# MCXN947_cm33_core0 register map
Vendor: nxp.com; File version: 1.0
CPU: CM33 r2p0, little endian, MPU, FPU, VTOR, 3 interrupt priority bits
Registers are 32-bit, read-write, reset 0x0 unless marked. A register's access mark holds for its fields unless they carry their own. Offsets are from the block's base; [hi:lo] are bit positions; {n}, {i} and the like mark numbered series; 'fields as' and 'values as' point back to an identical list.

## ENET0 (part 1 of 2) — ENET
Base 0x40100000
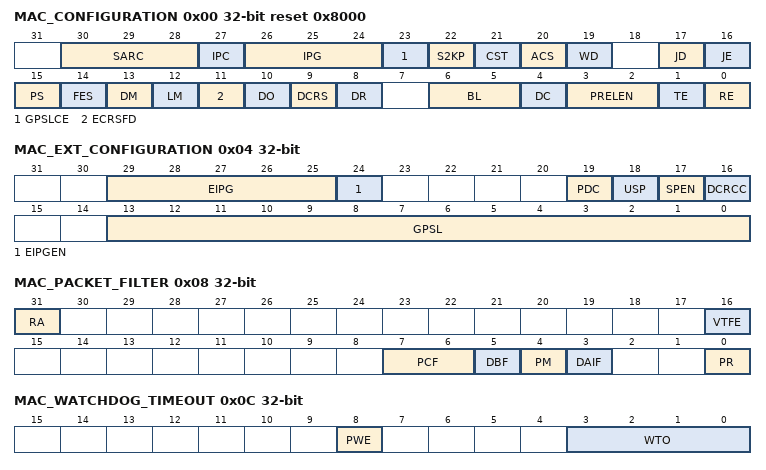
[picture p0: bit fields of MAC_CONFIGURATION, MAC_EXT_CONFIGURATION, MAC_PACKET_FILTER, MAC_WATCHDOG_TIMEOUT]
0x00 MAC_CONFIGURATION reset 0x8000
  [30:28] SARC — Source Address Insertion or Replacement Control
    0=SA_CTRL_IN (mti_sa_ctrl_i and ati_sa_ctrl_i input signals control the SA field generation); 2=MAC0_INS_SA (Contents of MAC Addr-0 inserted in SA field); 3=MAC0_REP_SA (Contents of MAC Addr-0 replaces SA field); 6=MAC1_INS_SA (Contents of MAC Addr-1 inserted in SA field); 7=MAC1_REP_SA (Contents of MAC Addr-1 replaces SA field)
  [27] IPC — Checksum Offload
    0=DISABLE (IP header/payload checksum checking is disabled); 1=ENABLE (IP header/payload checksum checking is enabled)
  [26:24] IPG — Inter-Packet Gap
    0=96 bit times IPG; 1=88 bit times IPG; 2=80 bit times IPG; 3=72 bit times IPG; 4=64 bit times IPG; 5=56 bit times IPG; 6=48 bit times IPG; 7=40 bit times IPG
  [23] GPSLCE — Giant Packet Size Limit Control Enable
    0=DISABLE (Giant Packet Size Limit Control is disabled); 1=ENABLE (Giant Packet Size Limit Control is enabled)
  [22] S2KP — IEEE 802.3as Support for 2K Packets
    0=DISABLE (Support upto 2K packet is disabled); 1=ENABLE (Support upto 2K packet is Enabled)
  [21] CST — CRC stripping for Type packets
    0=DISABLE (CRC stripping for Type packets is disabled); 1=ENABLE (CRC stripping for Type packets is enabled)
  [20] ACS — Automatic Pad or CRC Stripping
    0=DISABLE (Automatic Pad or CRC Stripping is disabled); 1=ENABLE (Automatic Pad or CRC Stripping is enabled)
  [19] WD — Watchdog Disable
    0=ENABLE (Watchdog is enabled); 1=DISABLE (Watchdog is disabled)
  [17] JD — Jabber Disable
    0=ENABLE (Jabber is enabled); 1=DISABLE (Jabber is disabled)
  [16] JE — Jumbo Packet Enable
    0=DISABLE (Jumbo packet is disabled); 1=ENABLE (Jumbo packet is enabled)
  [15] PS ro — Port Select
    0=M_1000_2500M (For 1000 or 2500 Mbps operations); 1=M_10_100M (For 10 or 100 Mbps operations)
  [14] FES — Speed
    0=M_10_1000M (10 Mbps when PS bit is 1 and 1 Gbps when PS bit is 0); 1=M_100_2500M (100 Mbps when PS bit is 1 and 2.5 Gbps when PS bit is 0)
  [13] DM — Duplex Mode
    0=HDUPLX (Half-duplex mode); 1=FDUPLX (Full-duplex mode)
  [12] LM — Loopback Mode
    0=DISABLE (Loopback is disabled); 1=ENABLE (Loopback is enabled)
  [11] ECRSFD — Enable Carrier Sense Before Transmission in Full-Duplex Mode
    0=DISABLE (ECRSFD is disabled); 1=ENABLE (ECRSFD is enabled)
  [10] DO — Disable Receive Own
    0=ENABLE (Enable Receive Own); 1=DISABLE (Disable Receive Own)
  [9] DCRS — Disable Carrier Sense During Transmission
    0=ENABLE (Enable Carrier Sense During Transmission); 1=DISABLE (Disable Carrier Sense During Transmission)
  [8] DR — Disable Retry
    0=ENABLE (Enable Retry); 1=DISABLE (Disable Retry)
  [6:5] BL — Back-Off Limit
    0=MIN_N_10 (k = min(n,10)); 1=MIN_N_8 (k = min(n,8)); 2=MIN_N_4 (k = min(n,4)); 3=MIN_N_1 (k = min(n,1))
  [4] DC — Deferral Check
    0=DISABLE (Deferral check function is disabled); 1=ENABLE (Deferral check function is enabled)
  [3:2] PRELEN — Preamble Length for Transmit packets
    0=M_7BYTES (7 bytes of preamble); 1=M_5BYTES (5 bytes of preamble); 2=M_3BYTES (3 bytes of preamble)
  [1] TE — Transmitter Enable
    0=DISABLE (Transmitter is disabled); 1=ENABLE (Transmitter is enabled)
  [0] RE — Receiver Enable
    0=DISABLE (Receiver is disabled); 1=ENABLE (Receiver is enabled)
0x04 MAC_EXT_CONFIGURATION — MAC Extended Configuration Register
  [29:25] EIPG — Extended Inter-Packet Gap
  [24] EIPGEN — Extended Inter-Packet Gap Enable
    0=DISABLE (Extended Inter-Packet Gap is disabled); 1=ENABLE (Extended Inter-Packet Gap is enabled)
  [19] PDC — Packet Duplication Control
    0=DISABLE (Packet Duplication Control is disabled); 1=ENABLE (Packet Duplication Control is enabled)
  [18] USP — Unicast Slow Protocol Packet Detect
    0=DISABLE (Unicast Slow Protocol Packet Detection is disabled); 1=ENABLE (Unicast Slow Protocol Packet Detection is enabled)
  [17] SPEN — Slow Protocol Detection Enable
    0=DISABLE (Slow Protocol Detection is disabled); 1=ENABLE (Slow Protocol Detection is enabled)
  [16] DCRCC — Disable CRC Checking for Received Packets
    0=ENABLE (CRC Checking is enabled); 1=DISABLE (CRC Checking is disabled)
  [13:0] GPSL — Giant Packet Size Limit
0x08 MAC_PACKET_FILTER
  [31] RA — Receive All
    0=DISABLE (Receive All is disabled); 1=ENABLE (Receive All is enabled)
  [16] VTFE — VLAN Tag Filter Enable
    0=DISABLE (VLAN Tag Filter is disabled); 1=ENABLE (VLAN Tag Filter is enabled)
  [7:6] PCF — Pass Control Packets
    0=FLTR_ALL (MAC filters all control packets from reaching the application); 1=FW_XCPT_PAU (MAC forwards all control packets except Pause packets to the application even if they fail the address filter); 2=FW_ALL (MAC forwards all control packets to the application even if they fail the address filter); 3=FW_PASS (MAC forwards the control packets that pass the Address filter)
  [5] DBF — Disable Broadcast Packets
    0=ENABLE (Enable Broadcast Packets); 1=DISABLE (Disable Broadcast Packets)
  [4] PM — Pass All Multicast
    0=DISABLE (Pass All Multicast is disabled); 1=ENABLE (Pass All Multicast is enabled)
  [3] DAIF — DA Inverse Filtering
    0=DISABLE (DA Inverse Filtering is disabled); 1=ENABLE (DA Inverse Filtering is enabled)
  [0] PR — Promiscuous Mode
    0=DISABLE (Promiscuous Mode is disabled); 1=ENABLE (Promiscuous Mode is enabled)
0x0C MAC_WATCHDOG_TIMEOUT — Watchdog Timeout
  [8] PWE — Programmable Watchdog Enable
    0=DISABLE (Programmable Watchdog is disabled); 1=ENABLE (Programmable Watchdog is enabled)
  [3:0] WTO — Watchdog Timeout
    {v}=bf_{v+2}KBYTES ({v+2} KB) (v=0..13); 14=bf_16383BYTES (16383 Bytes)
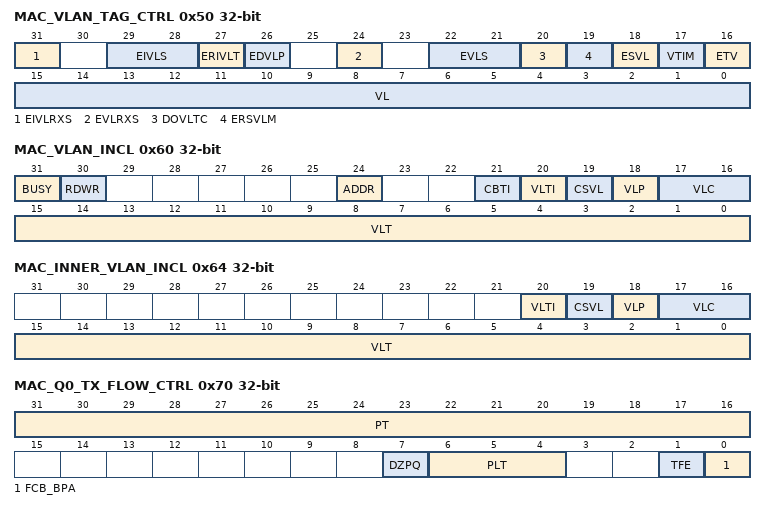
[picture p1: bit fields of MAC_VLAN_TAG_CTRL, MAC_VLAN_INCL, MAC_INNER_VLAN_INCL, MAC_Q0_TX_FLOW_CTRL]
0x50 MAC_VLAN_TAG_CTRL — MAC VLAN Tag Control
  [31] EIVLRXS — Enable Inner VLAN Tag in Rx Status
    0=DISABLE (Inner VLAN Tag in Rx status is disabled); 1=ENABLE (Inner VLAN Tag in Rx status is enabled)
  [29:28] EIVLS — Enable Inner VLAN Tag Stripping on Receive
    0=DONOT (Do not strip); 1=IFPASS (Strip if VLAN filter passes); 2=IFFAIL (Strip if VLAN filter fails); 3=ALWAYS (Always strip)
  [27] ERIVLT — Enable Inner VLAN Tag
    0=DISABLE (Inner VLAN tag is disabled); 1=ENABLE (Inner VLAN tag is enabled)
  [26] EDVLP — Enable Double VLAN Processing
    0=DISABLE (Double VLAN Processing is disabled); 1=ENABLE (Double VLAN Processing is enabled)
  [24] EVLRXS — Enable VLAN Tag in Rx status
    0=DISABLE (VLAN Tag in Rx status is disabled); 1=ENABLE (VLAN Tag in Rx status is enabled)
  [22:21] EVLS — Enable VLAN Tag Stripping on Receive
    values as EIVLS
  [20] DOVLTC — Disable VLAN Type Check
    0=ENABLE (VLAN Type Check is enabled); 1=DISABLE (VLAN Type Check is disabled)
  [19] ERSVLM — Enable Receive S-VLAN Match
    0=DISABLE (Receive S-VLAN Match is disabled); 1=ENABLE (Receive S-VLAN Match is enabled)
  [18] ESVL — Enable S-VLAN
    0=DISABLE (S-VLAN is disabled); 1=ENABLE (S-VLAN is enabled)
  [17] VTIM — VLAN Tag Inverse Match Enable
    0=DISABLE (VLAN Tag Inverse Match is disabled); 1=ENABLE (VLAN Tag Inverse Match is enabled)
  [16] ETV — Enable 12-Bit VLAN Tag Comparison
    0=DISABLE (12-bit VLAN Tag Comparison is disabled); 1=ENABLE (12-bit VLAN Tag Comparison is enabled)
  [15:0] VL — VLAN Tag Identifier for Receive Packets
0x60 MAC_VLAN_INCL — VLAN Tag Inclusion or Replacement
  [31] BUSY ro
    0=INACTIVE (Busy status not detected); 1=ACTIVE (Busy status detected)
  [30] RDWR — Read write control
    0=READ (Read operation of indirect access); 1=WRITE (Write operation of indirect access)
  [24] ADDR — Address
  [21] CBTI — Channel based tag insertion
    0=DISABLE (Channel based tag insertion is disabled); 1=ENABLE (Channel based tag insertion is enabled)
  [20] VLTI — VLAN Tag Input
    0=DISABLE (VLAN Tag Input is disabled); 1=ENABLE (VLAN Tag Input is enabled)
  [19] CSVL — C-VLAN or S-VLAN
    0=C_VLAN (C-VLAN type (0x8100) is inserted or replaced); 1=S_VLAN (S-VLAN type (0x88A8) is inserted or replaced)
  [18] VLP — VLAN Priority Control
    0=DISABLE (VLAN Priority Control is disabled); 1=ENABLE (VLAN Priority Control is enabled)
  [17:16] VLC — VLAN Tag Control in Transmit Packets
    0=NONE (No VLAN tag deletion, insertion, or replacement); 1=DELETE (VLAN tag deletion); 2=INSERT (VLAN tag insertion); 3=REPLACE (VLAN tag replacement)
  [15:0] VLT — VLAN Tag for Transmit Packets
0x64 MAC_INNER_VLAN_INCL — MAC Inner VLAN Tag Inclusion or Replacement
  [20] VLTI — VLAN Tag Input
    values as MAC_VLAN_INCL.VLTI
  [19] CSVL — C-VLAN or S-VLAN
    0=CVLAN (C-VLAN type (0x8100) is inserted); 1=SVLAN (S-VLAN type (0x88A8) is inserted)
  [18] VLP — VLAN Priority Control
    values as MAC_VLAN_INCL.VLP
  [17:16] VLC — VLAN Tag Control in Transmit Packets
    values as MAC_VLAN_INCL.VLC
  [15:0] VLT — VLAN Tag for Transmit Packets
0x70 MAC_Q0_TX_FLOW_CTRL — MAC Q0 Tx Flow Control
  [31:16] PT — Pause Time
  [7] DZPQ — Disable Zero-Quanta Pause
    0=ENABLE (Zero-Quanta Pause packet generation is enabled); 1=DISABLE (Zero-Quanta Pause packet generation is disabled)
  [6:4] PLT — Pause Low Threshold
    0=PT4 (Pause Time minus 4 Slot Times (PT -4 slot times)); 1=PT28 (Pause Time minus 28 Slot Times (PT -28 slot times)); 2=PT36 (Pause Time minus 36 Slot Times (PT -36 slot times)); 3=PT144 (Pause Time minus 144 Slot Times (PT -144 slot times)); 4=PT256 (Pause Time minus 256 Slot Times (PT -256 slot times)); 5=PT512 (Pause Time minus 512 Slot Times (PT -512 slot times))
  [1] TFE — Transmit Flow Control Enable
    0=DISABLE (Transmit Flow Control is disabled); 1=ENABLE (Transmit Flow Control is enabled)
  [0] FCB_BPA — Flow Control Busy or Backpressure Activate
    0=DISABLE (Flow Control Busy or Backpressure Activate is disabled); 1=ENABLE (Flow Control Busy or Backpressure Activate is enabled)
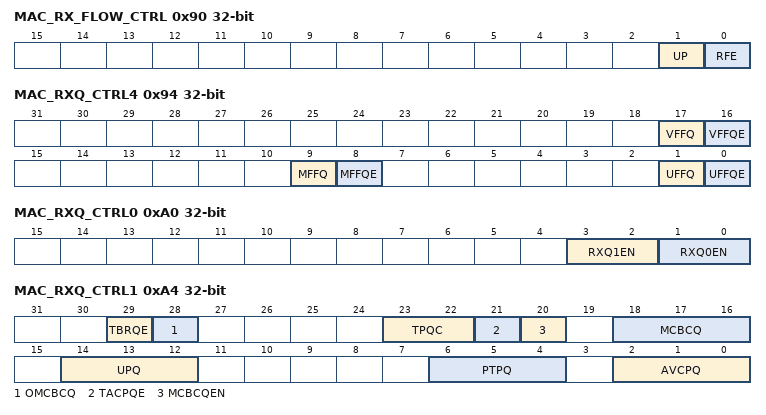
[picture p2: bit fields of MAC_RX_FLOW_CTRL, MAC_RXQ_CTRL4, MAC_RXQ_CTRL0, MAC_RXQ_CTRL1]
0x90 MAC_RX_FLOW_CTRL — MAC Rx Flow Control
  [1] UP — Unicast Pause Packet Detect
    0=DISABLE (Unicast Pause Packet Detect disabled); 1=ENABLE (Unicast Pause Packet Detect enabled)
  [0] RFE — Receive Flow Control Enable
    0=DISABLE (Receive Flow Control is disabled); 1=ENABLE (Receive Flow Control is enabled)
0x94 MAC_RXQ_CTRL4 — Receive Queue Control 4
  [17] VFFQ — VLAN Tag Filter Fail Packets Queue
  [16] VFFQE — VLAN Tag Filter Fail Packets Queuing Enable
    0=DISABLE (VLAN tag Filter Fail Packets Queuing is disabled); 1=ENABLE (VLAN tag Filter Fail Packets Queuing is enabled)
  [9] MFFQ — Multicast Address Filter Fail Packets Queue.
  [8] MFFQE — Multicast Address Filter Fail Packets Queuing Enable.
    0=DISABLE (Multicast Address Filter Fail Packets Queuing is disabled); 1=ENABLE (Multicast Address Filter Fail Packets Queuing is enabled)
  [1] UFFQ — Unicast Address Filter Fail Packets Queue.
  [0] UFFQE — Unicast Address Filter Fail Packets Queuing Enable.
    0=DISABLE (Unicast Address Filter Fail Packets Queuing is disabled); 1=ENABLE (Unicast Address Filter Fail Packets Queuing is enabled)
0xA0 MAC_RXQ_CTRL0 — Receive Queue Control 0
  [3:2] RXQ1EN — Receive Queue 1 Enable
    0=DISABLE (Queue not enabled); 1=EN_AV (Queue enabled for AV); 2=EN_DCB_GEN (Queue enabled for DCB/Generic)
  [1:0] RXQ0EN — Receive Queue 0 Enable
    values as RXQ1EN
0xA4 MAC_RXQ_CTRL1 — Receive Queue Control 1
  [29] TBRQE — Type Field Based Rx Queuing Enable
  [28] OMCBCQ
    0=DISABLE (overriding MCBCQ priority disabled); 1=ENABLE (overriding MCBCQ priority enabled)
  [23:22] TPQC — Tagged PTP over Ethernet Packets Queuing Control.
  [21] TACPQE — Tagged AV Control Packets Queuing Enable.
    0=DISABLE (Tagged AV Control Packets Queuing is disabled); 1=ENABLE (Tagged AV Control Packets Queuing is enabled)
  [20] MCBCQEN — Multicast and Broadcast Queue Enable
    0=DISABLE (Multicast and Broadcast Queue is disabled); 1=ENABLE (Multicast and Broadcast Queue is enabled)
  [18:16] MCBCQ — Multicast and Broadcast Queue
    0=QUEUE0 (Receive Queue 0); 1=QUEUE1 (Receive Queue 1)
  [14:12] UPQ — Untagged Packet Queue
    0=QUEUE0 (Receive Queue 0); 1=QUEUE1 (Receive Queue 1)
  [6:4] PTPQ — PTP Packets Queue
    0=QUEUE0 (Receive Queue 0); 1=QUEUE1 (Receive Queue 1)
  [2:0] AVCPQ — AV Untagged Control Packets Queue
    0=QUEUE0 (Receive Queue 0); 1=QUEUE1 (Receive Queue 1)
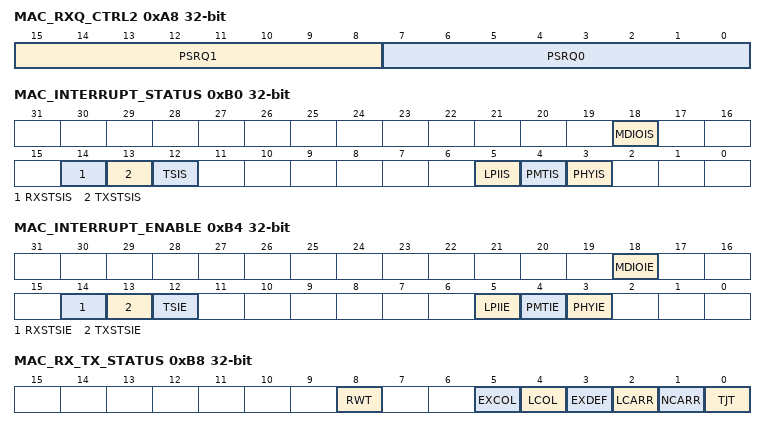
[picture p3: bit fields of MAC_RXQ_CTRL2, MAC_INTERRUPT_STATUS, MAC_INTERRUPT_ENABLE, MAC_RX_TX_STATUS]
0xA8 MAC_RXQ_CTRL2 — Receive Queue Control 2
  [15:8] PSRQ1 — Priorities Selected in the Receive Queue 1
  [7:0] PSRQ0 — Priorities Selected in the Receive Queue 0
0xB0 MAC_INTERRUPT_STATUS ro — Interrupt Status
  [18] MDIOIS — MDIO Interrupt Status
    0=INACTIVE (MDIO Interrupt status not active); 1=ACTIVE (MDIO Interrupt status active)
  [14] RXSTSIS — Receive Status Interrupt
    0=INACTIVE (Receive Interrupt status not active); 1=ACTIVE (Receive Interrupt status active)
  [13] TXSTSIS — Transmit Status Interrupt
    0=INACTIVE (Transmit Interrupt status not active); 1=ACTIVE (Transmit Interrupt status active)
  [12] TSIS
    0=INACTIVE (Timestamp Interrupt status not active); 1=ACTIVE (Timestamp Interrupt status active)
  [5] LPIIS
    0=INACTIVE (LPI Interrupt status not active); 1=ACTIVE (LPI Interrupt status active)
  [4] PMTIS
    0=INACTIVE (PMT Interrupt status not active); 1=ACTIVE (PMT Interrupt status active)
  [3] PHYIS — PHY Interrupt
    0=INACTIVE (PHY Interrupt not detected); 1=ACTIVE (PHY Interrupt detected)
0xB4 MAC_INTERRUPT_ENABLE — Interrupt Enable
  [18] MDIOIE — MDIO Interrupt Enable
    0=DISABLE (MDIO Interrupt is disabled); 1=ENABLE (MDIO Interrupt is enabled)
  [14] RXSTSIE — Receive Status Interrupt Enable
    0=DISABLE (Receive Status Interrupt is disabled); 1=ENABLE (Receive Status Interrupt is enabled)
  [13] TXSTSIE — Transmit Status Interrupt Enable
    0=DISABLE (Timestamp Status Interrupt is disabled); 1=ENABLE (Timestamp Status Interrupt is enabled)
  [12] TSIE — Timestamp Interrupt Enable
    0=DISABLE (Timestamp Interrupt is disabled); 1=ENABLE (Timestamp Interrupt is enabled)
  [5] LPIIE — LPI Interrupt Enable
    0=DISABLE (LPI Interrupt is disabled); 1=ENABLE (LPI Interrupt is enabled)
  [4] PMTIE — PMT Interrupt Enable
    0=DISABLE (PMT Interrupt is disabled); 1=ENABLE (PMT Interrupt is enabled)
  [3] PHYIE — PHY Interrupt Enable
    0=DISABLE (PHY Interrupt is disabled); 1=ENABLE (PHY Interrupt is enabled)
0xB8 MAC_RX_TX_STATUS ro — Receive Transmit Status
  [8] RWT — Receive Watchdog Timeout
    0=INACTIVE (No receive watchdog timeout); 1=ACTIVE (Receive watchdog timed out)
  [5] EXCOL — Excessive Collisions
    0=INACTIVE (No collision); 1=ACTIVE (Excessive collision is sensed)
  [4] LCOL — Late Collision
    0=INACTIVE (No collision); 1=ACTIVE (Late collision is sensed)
  [3] EXDEF — Excessive Deferral
    0=INACTIVE (No Excessive deferral); 1=ACTIVE (Excessive deferral)
  [2] LCARR — Loss of Carrier
    0=INACTIVE (Carrier is present); 1=ACTIVE (Loss of carrier)
  [1] NCARR — No Carrier
    0=INACTIVE (Carrier is present); 1=ACTIVE (No carrier)
  [0] TJT — Transmit Jabber Timeout
    0=INACTIVE (No Transmit Jabber Timeout); 1=ACTIVE (Transmit Jabber Timeout occurred)
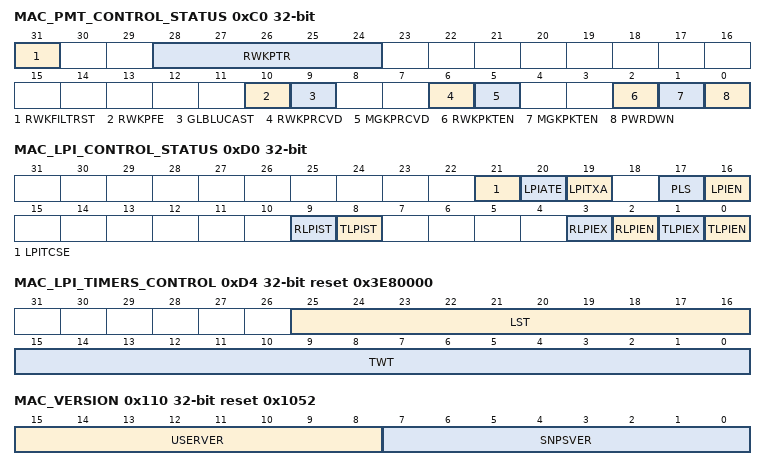
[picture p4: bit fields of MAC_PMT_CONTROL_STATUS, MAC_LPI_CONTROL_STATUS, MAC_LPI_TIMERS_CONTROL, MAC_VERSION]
0xC0 MAC_PMT_CONTROL_STATUS — PMT Control and Status
  [31] RWKFILTRST — Remote Wake-Up Packet Filter Register Pointer Reset
    0=DISABLE (Remote Wake-Up Packet Filter Register Pointer is not Reset); 1=ENABLE (Remote Wake-Up Packet Filter Register Pointer is Reset)
  [28:24] RWKPTR ro — Remote Wake-up FIFO Pointer
  [10] RWKPFE — Remote Wake-up Packet Forwarding Enable
    0=DISABLE (Remote Wake-up Packet Forwarding is disabled); 1=ENABLE (Remote Wake-up Packet Forwarding is enabled)
  [9] GLBLUCAST — Global Unicast
    0=DISABLE (Global unicast is disabled); 1=ENABLE (Global unicast is enabled)
  [6] RWKPRCVD ro — Remote Wake-Up Packet Received
    0=INACTIVE (Remote wake-up packet is received); 1=ACTIVE (Remote wake-up packet is received)
  [5] MGKPRCVD ro — Magic Packet Received
    0=INACTIVE (No Magic packet is received); 1=ACTIVE (Magic packet is received)
  [2] RWKPKTEN — Remote Wake-Up Packet Enable
    0=DISABLE (Remote wake-up packet is disabled); 1=ENABLE (Remote wake-up packet is enabled)
  [1] MGKPKTEN — Magic Packet Enable
    0=DISABLE (Magic Packet is disabled); 1=ENABLE (Magic Packet is enabled)
  [0] PWRDWN — Power Down
    0=DISABLE (Power down is disabled); 1=ENABLE (Power down is enabled)
0xC4 MAC_RWK_PACKET_FILTER — Remote Wakeup Filter
  [31:0] WKUPFRMFTR — RWK Packet Filter
0xD0 MAC_LPI_CONTROL_STATUS — LPI Control and Status
  [21] LPITCSE — LPI Tx Clock Stop Enable
    0=DISABLE (LPI Tx Clock Stop is disabled); 1=ENABLE (LPI Tx Clock Stop is enabled)
  [20] LPIATE — LPI Timer Enable
    0=DISABLE (LPI Timer is disabled); 1=ENABLE (LPI Timer is enabled)
  [19] LPITXA — LPI Tx Automate
    0=DISABLE (LPI Tx Automate is disabled); 1=ENABLE (LPI Tx Automate is enabled)
  [17] PLS — PHY Link Status
    0=DISABLE (link is down); 1=ENABLE (link is okay (UP))
  [16] LPIEN — LPI Enable
    0=DISABLE (LPI state is disabled); 1=ENABLE (LPI state is enabled)
  [9] RLPIST ro — Receive LPI State
    0=INACTIVE (Receive LPI state not detected); 1=ACTIVE (Receive LPI state detected)
  [8] TLPIST ro — Transmit LPI State
    0=INACTIVE (Transmit LPI state not detected); 1=ACTIVE (Transmit LPI state detected)
  [3] RLPIEX ro — Receive LPI Exit
    0=INACTIVE (Receive LPI exit not detected); 1=ACTIVE (Receive LPI exit detected)
  [2] RLPIEN ro — Receive LPI Entry
    0=INACTIVE (Receive LPI entry not detected); 1=ACTIVE (Receive LPI entry detected)
  [1] TLPIEX ro — Transmit LPI Exit
    0=INACTIVE (Transmit LPI exit not detected); 1=ACTIVE (Transmit LPI exit detected)
  [0] TLPIEN ro — Transmit LPI Entry
    0=INACTIVE (Transmit LPI entry not detected); 1=ACTIVE (Transmit LPI entry detected)
0xD4 MAC_LPI_TIMERS_CONTROL reset 0x3E80000 — LPI Timers Control
  [25:16] LST — LPI LS Timer
  [15:0] TWT — LPI TW Timer
0xD8 MAC_LPI_ENTRY_TIMER — Tx LPI Entry Timer Control
  [19:3] LPIET — LPI Entry Timer
0xDC MAC_ONEUS_TIC_COUNTER reset 0x63 — One-microsecond Reference Timer
  [11:0] TIC_1US_CNTR — 1US TIC Counter
0x110 MAC_VERSION ro reset 0x1052
  [15:8] USERVER — User-defined Version
  [7:0] SNPSVER — Synopsys-defined Version
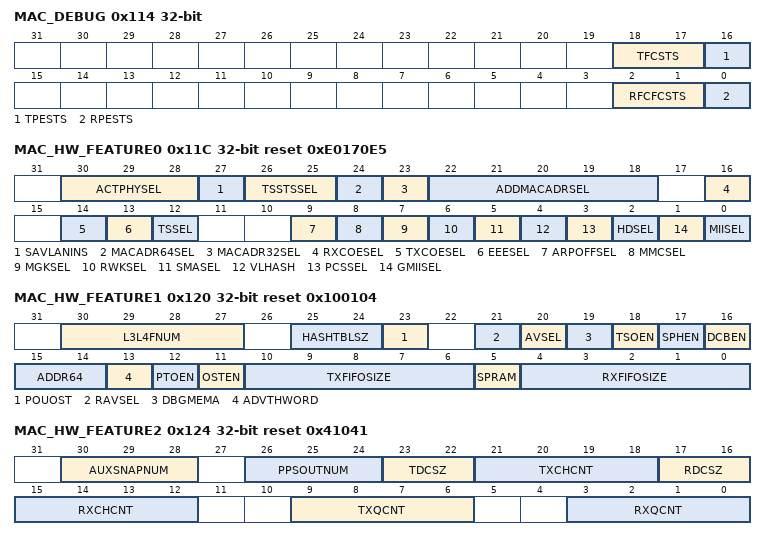
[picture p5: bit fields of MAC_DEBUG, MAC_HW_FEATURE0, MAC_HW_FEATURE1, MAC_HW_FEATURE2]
0x114 MAC_DEBUG ro
  [18:17] TFCSTS — MAC Transmit Packet Controller Status
    0=IDLE (Idle state); 1=WAITING (Waiting for one of the following: Status of the previous packet OR IPG or back off period to be over); 2=GEN_TX_PAU (Generating and transmitting a Pause control packet (in full-duplex mode)); 3=TRNSFR (Transferring input packet for transmission)
  [16] TPESTS — MAC GMII or MII Transmit Protocol Engine Status
    0=INACTIVE (MAC GMII or MII Transmit Protocol Engine Status not detected); 1=ACTIVE (MAC GMII or MII Transmit Protocol Engine Status detected)
  [2:1] RFCFCSTS — MAC Receive Packet Controller FIFO Status
  [0] RPESTS — MAC GMII or MII Receive Protocol Engine Status
    0=INACTIVE (MAC GMII or MII Receive Protocol Engine Status not detected); 1=ACTIVE (MAC GMII or MII Receive Protocol Engine Status detected)
0x11C MAC_HW_FEATURE0 ro reset 0xE0170E5 — Hardware Features 0
  [30:28] ACTPHYSEL — Active PHY Selected
    0=GMII_MII (GMII or MII); 1=RGMII; 2=SGMII; 3=TBI; 4=RMII; 5=RTBI; 6=SMII; 7=REVMIII
  [27] SAVLANINS — Source Address or VLAN Insertion Enable
    0=INACTIVE (Source Address or VLAN Insertion Enable option is not selected); 1=ACTIVE (Source Address or VLAN Insertion Enable option is selected)
  [26:25] TSSTSSEL — Timestamp System Time Source
    0=INTRNL (Internal); 1=EXTRNL (External); 2=BOTH
  [24] MACADR64SEL — MAC Addresses 64-127 Selected
    0=INACTIVE (MAC Addresses 64-127 Select option is not selected); 1=ACTIVE (MAC Addresses 64-127 Select option is selected)
  [23] MACADR32SEL — MAC Addresses 32-63 Selected
    0=INACTIVE (MAC Addresses 32-63 Select option is not selected); 1=ACTIVE (MAC Addresses 32-63 Select option is selected)
  [22:18] ADDMACADRSEL — MAC Addresses 1-31 Selected
  [16] RXCOESEL — Receive Checksum Offload Enabled
    0=INACTIVE (Receive Checksum Offload Enable option is not selected); 1=ACTIVE (Receive Checksum Offload Enable option is selected)
  [14] TXCOESEL — Transmit Checksum Offload Enabled
    0=INACTIVE (Transmit Checksum Offload Enable option is not selected); 1=ACTIVE (Transmit Checksum Offload Enable option is selected)
  [13] EEESEL — Energy Efficient Ethernet Enabled
    0=INACTIVE (Energy Efficient Ethernet Enable option is not selected); 1=ACTIVE (Energy Efficient Ethernet Enable option is selected)
  [12] TSSEL — IEEE 1588-2008 Timestamp Enabled
    0=INACTIVE (IEEE 1588-2008 Timestamp Enable option is not selected); 1=ACTIVE (IEEE 1588-2008 Timestamp Enable option is selected)
  [9] ARPOFFSEL — ARP Offload Enabled
    0=INACTIVE (ARP Offload Enable option is not selected); 1=ACTIVE (ARP Offload Enable option is selected)
  [8] MMCSEL — RMON Module Enable
    0=INACTIVE (RMON Module Enable option is not selected); 1=ACTIVE (RMON Module Enable option is selected)
  [7] MGKSEL — PMT Magic Packet Enable
    0=INACTIVE (PMT Magic Packet Enable option is not selected); 1=ACTIVE (PMT Magic Packet Enable option is selected)
  [6] RWKSEL — PMT Remote Wake-up Packet Enable
    0=INACTIVE (PMT Remote Wake-up Packet Enable option is not selected); 1=ACTIVE (PMT Remote Wake-up Packet Enable option is selected)
  [5] SMASEL — SMA (MDIO) Interface
    0=INACTIVE (SMA (MDIO) Interface not selected); 1=ACTIVE (SMA (MDIO) Interface selected)
  [4] VLHASH — VLAN Hash Filter Selected
    0=INACTIVE (VLAN Hash Filter not selected); 1=ACTIVE (VLAN Hash Filter selected)
  [3] PCSSEL — PCS Registers (TBI, SGMII, or RTBI PHY interface)
    0=INACTIVE (No PCS Registers (TBI, SGMII, or RTBI PHY interface)); 1=ACTIVE (PCS Registers (TBI, SGMII, or RTBI PHY interface))
  [2] HDSEL — Half-duplex Support
    0=INACTIVE (No Half-duplex support); 1=ACTIVE (Half-duplex support)
  [1] GMIISEL — 1000 Mbps Support
    0=INACTIVE (No 1000 Mbps support); 1=ACTIVE (1000 Mbps support)
  [0] MIISEL — 10 or 100 Mbps Support
    0=INACTIVE (No 10 or 100 Mbps support); 1=ACTIVE (10 or 100 Mbps support)
0x120 MAC_HW_FEATURE1 ro reset 0x100104 — Hardware Features 1
  [30:27] L3L4FNUM — Total number of L3 or L4 Filters
    0=NOFILT (No L3 or L4 Filter); 1=M_1FILT (1 L3 or L4 Filter); {v}=M_{v}FILT ({v} L3 or L4 Filters) (v=2..8)
  [25:24] HASHTBLSZ — Hash Table Size
    0=NO_HT (No hash table); 1=M_64 (64); 2=M_128 (128); 3=M_256 (256)
  [23] POUOST — One Step for PTP over UDP/IP Feature Enable
    0=INACTIVE (One Step for PTP over UDP/IP Feature is not selected); 1=ACTIVE (One Step for PTP over UDP/IP Feature is selected)
  [21] RAVSEL — Rx Side Only AV Feature Enable
    0=INACTIVE (Rx Side Only AV Feature is not selected); 1=ACTIVE (Rx Side Only AV Feature is selected)
  [20] AVSEL — AV Feature Enable
    0=INACTIVE (AV Feature is not selected); 1=ACTIVE (AV Feature is selected)
  [19] DBGMEMA — DMA Debug Registers Enable
    0=INACTIVE (DMA Debug Registers option is not selected); 1=ACTIVE (DMA Debug Registers option is selected)
  [18] TSOEN — TCP Segmentation Offload Enable
    0=INACTIVE (TCP Segmentation Offload Feature is not selected); 1=ACTIVE (TCP Segmentation Offload Feature is selected)
  [17] SPHEN — Split Header Feature Enable
    0=INACTIVE (Split Header Feature is not selected); 1=ACTIVE (Split Header Feature is selected)
  [16] DCBEN — DCB Feature Enable
    0=INACTIVE (DCB Feature is not selected); 1=ACTIVE (DCB Feature is selected)
  [15:14] ADDR64 — Address Width.
    0=M_32 (32); 1=M_40 (40); 2=M_48 (48)
  [13] ADVTHWORD — IEEE 1588 High Word Register Enable
    0=INACTIVE (IEEE 1588 High Word Register option is not selected); 1=ACTIVE (IEEE 1588 High Word Register option is selected)
  [12] PTOEN — PTP Offload Enable
    0=INACTIVE (PTP Offload feature is not selected); 1=ACTIVE (PTP Offload feature is selected)
  [11] OSTEN — One-Step Timestamping Enable
    0=INACTIVE (One-Step Timestamping feature is not selected); 1=ACTIVE (One-Step Timestamping feature is selected)
  [10:6] TXFIFOSIZE — MTL Transmit FIFO Size
    0=M_128B (128 bytes); 1=M_256B (256 bytes); 2=M_512B (512 bytes); 3=M_1024B (1024 bytes); 4=M_2048B (2048 bytes); 5=M_4096B (4096 bytes); 6=M_8192B (8192 bytes); 7=M_16384B (16384 bytes); 8=M_32KB (32 KB); 9=M_64KB (64 KB); 10=M_128KB (128 KB)
  [5] SPRAM — Single Port RAM Enable
    0=INACTIVE (Single Port RAM feature is not selected); 1=ACTIVE (Single Port RAM feature is selected)
  [4:0] RXFIFOSIZE — MTL Receive FIFO Size
    0=M_128B (128 bytes); 1=M_256B (256 bytes); 2=M_512B (512 bytes); 3=M_1024B (1024 bytes); 4=M_2048B (2048 bytes); 5=M_4096B (4096 bytes); 6=M_8192B (8192 bytes); 7=M_16384B (16384 bytes); 8=M_32KB (32 KB); 9=M_64KB (64 KB); 10=M_128KB (128 KB); 11=M_256KB (256 KB)
0x124 MAC_HW_FEATURE2 ro reset 0x41041 — Hardware Features 2
  [30:28] AUXSNAPNUM — Number of Auxiliary Snapshot Inputs
    0=NO_AUXI (No auxiliary input); {v}=M_{v}_AUXI ({v} auxiliary input) (v=1..4)
  [26:24] PPSOUTNUM — Number of PPS Outputs
    0=NO_PPSO (No PPS output); {v}=M_{v}_PPSO ({v} PPS output) (v=1..4)
  [23:22] TDCSZ — Tx DMA Descriptor Cache Size in terms of 16 bytes descriptors:
  [21:18] TXCHCNT — Number of DMA Transmit Channels
    0=M_1TXCH (1 MTL Tx Channel); {v}=M_{v+1}TXCH ({v+1} MTL Tx Channels) (v=1..7)
  [17:16] RDCSZ — Rx DMA Descriptor Cache Size in terms of 16 bytes descriptors:
  [15:12] RXCHCNT — Number of DMA Receive Channels
    0=M_1RXCH (1 MTL Rx Channel); {v}=M_{v+1}RXCH ({v+1} MTL Rx Channels) (v=1..7)
  [9:6] TXQCNT — Number of MTL Transmit Queues
    0=M_1TXQ (1 MTL Tx Queue); {v}=M_{v+1}TXQ ({v+1} MTL Tx Queues) (v=1..7)
  [3:0] RXQCNT — Number of MTL Receive Queues
    0=M_1RXQ (1 MTL Rx Queue); {v}=M_{v+1}RXQ ({v+1} MTL Rx Queues) (v=1..7)
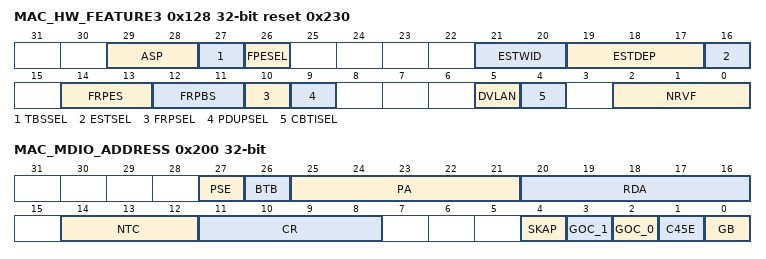
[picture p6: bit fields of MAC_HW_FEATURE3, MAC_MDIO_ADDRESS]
0x128 MAC_HW_FEATURE3 ro reset 0x230 — Hardware Features 3
  [29:28] ASP — Automotive Safety Package
    0=NONE (No Safety features selected); 1=ECC_ONLY (Only "ECC protection for external memory" feature is selected); 2=AS_NPPE (All the Automotive Safety features are selected without the "Parity Port Enable for external interface" feature); 3=AS_PPE (All the Automotive Safety features are selected with the "Parity Port Enable for external interface" feature)
  [27] TBSSEL — Time Based Scheduling Enable
    0=INACTIVE (Time Based Scheduling Enable feature is not selected); 1=ACTIVE (Time Based Scheduling Enable feature is selected)
  [26] FPESEL — Frame Preemption Enable
    0=INACTIVE (Frame Preemption Enable feature is not selected); 1=ACTIVE (Frame Preemption Enable feature is selected)
  [21:20] ESTWID — Width of the Time Interval field in the Gate Control List
    0=NOWIDTH (Width not configured); 1=WIDTH16 (16); 2=WIDTH20 (20); 3=WIDTH24 (24)
  [19:17] ESTDEP — Depth of the Gate Control List
    0=NODEPTH (No Depth configured); 1=DEPTH64 (64); 2=DEPTH128 (128); 3=DEPTH256 (256); 4=DEPTH512 (512); 5=DEPTH1024 (1024)
  [16] ESTSEL — Enhancements to Scheduled Traffic Enable
    0=INACTIVE (Enable Enhancements to Scheduling Traffic feature is not selected); 1=ACTIVE (Enable Enhancements to Scheduling Traffic feature is selected)
  [14:13] FRPES — Flexible Receive Parser Table Entries size
    0=M_64ENTR (64 Entries); 1=M_128ENTR (128 Entries); 2=M_256ENTR (256 Entries)
  [12:11] FRPBS — Flexible Receive Parser Buffer size
    0=M_64BYTES (64 Bytes); 1=M_128BYTES (128 Bytes); 2=M_256BYTES (256 Bytes)
  [10] FRPSEL — Flexible Receive Parser Selected
    0=INACTIVE (Flexible Receive Parser feature is not selected); 1=ACTIVE (Flexible Receive Parser feature is selected)
  [9] PDUPSEL — Broadcast/Multicast Packet Duplication
    0=INACTIVE (Broadcast/Multicast Packet Duplication feature is not selected); 1=ACTIVE (Broadcast/Multicast Packet Duplication feature is selected)
  [5] DVLAN — Double VLAN Tag Processing Selected
    0=INACTIVE (Double VLAN option is not selected); 1=ACTIVE (Double VLAN option is selected)
  [4] CBTISEL — Queue/Channel based VLAN tag insertion on Tx Enable
    0=INACTIVE (Enable Queue/Channel based VLAN tag insertion on Tx feature is not selected); 1=ACTIVE (Enable Queue/Channel based VLAN tag insertion on Tx feature is selected)
  [2:0] NRVF — Number of Extended VLAN Tag Filters Enabled
    0=NO_ERVLAN (No Extended Rx VLAN Filters); 1=M_4_ERVLAN (4 Extended Rx VLAN Filters); 2=M_8_ERVLAN (8 Extended Rx VLAN Filters); 3=M_16_ERVLAN (16 Extended Rx VLAN Filters); 4=M_24_ERVLAN (24 Extended Rx VLAN Filters); 5=M_32_ERVLAN (32 Extended Rx VLAN Filters)
0x200 MAC_MDIO_ADDRESS — MDIO Address
  [27] PSE — Preamble Suppression Enable
    0=DISABLE (Preamble Suppression disabled); 1=ENABLE (Preamble Suppression enabled)
  [26] BTB — Back to Back transactions
    0=DISABLE (Back to Back transactions disabled); 1=ENABLE (Back to Back transactions enabled)
  [25:21] PA — Physical Layer Address
  [20:16] RDA — Register/Device Address
  [14:12] NTC
  [11:8] CR
  [4] SKAP — Skip Address Packet
    0=DISABLE (Skip Address Packet is disabled); 1=ENABLE (Skip Address Packet is enabled)
  [3] GOC_1 — GMII Operation Command 1
    0=DISABLE (GMII Operation Command 1 is disabled); 1=ENABLE (GMII Operation Command 1 is enabled)
  [2] GOC_0 — GMII Operation Command 0
    0=DISABLE (GMII Operation Command 0 is disabled); 1=ENABLE (GMII Operation Command 0 is enabled)
  [1] C45E — Clause 45 PHY Enable
    0=DISABLE (Clause 45 PHY is disabled); 1=ENABLE (Clause 45 PHY is enabled)
  [0] GB — GMII Busy
    0=DISABLE (GMII Busy is disabled); 1=ENABLE (GMII Busy is enabled)
